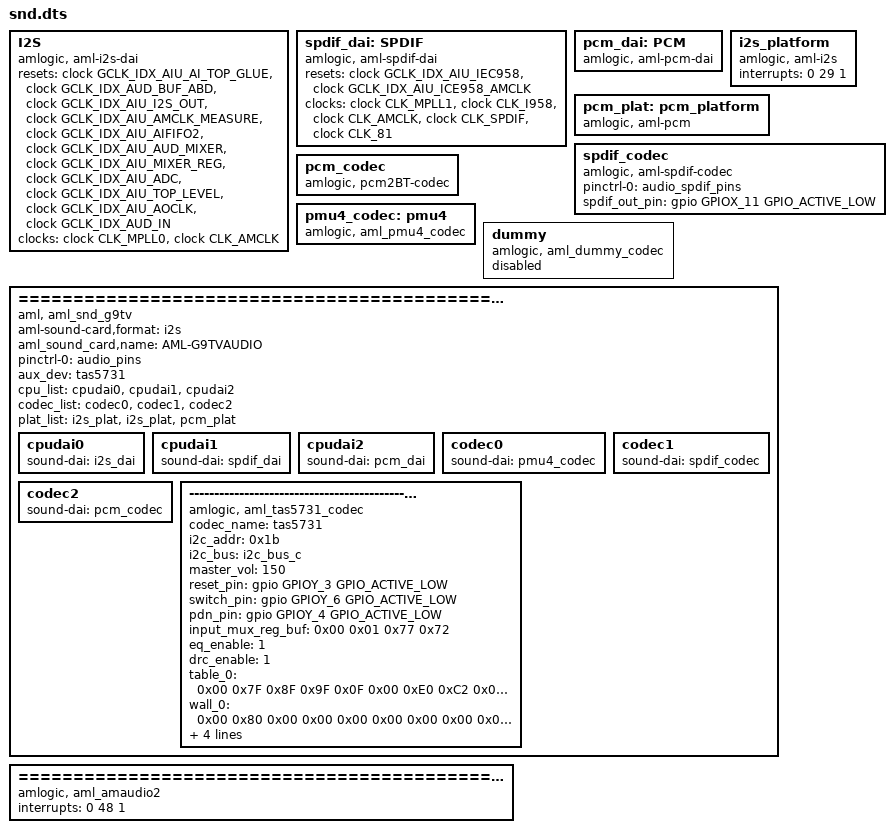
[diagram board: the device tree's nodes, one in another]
	/* AUDIO MESON8 DEVICES */
================================================================================================
	i2s_dai: I2S {
		#sound-dai-cells = <0>;
		resets = <
			&clock GCLK_IDX_AIU_AI_TOP_GLUE
			&clock GCLK_IDX_AUD_BUF_ABD
			&clock GCLK_IDX_AIU_I2S_OUT
			&clock GCLK_IDX_AIU_AMCLK_MEASURE
			&clock GCLK_IDX_AIU_AIFIFO2
			&clock GCLK_IDX_AIU_AUD_MIXER
			&clock GCLK_IDX_AIU_MIXER_REG
			&clock GCLK_IDX_AIU_ADC
			&clock GCLK_IDX_AIU_TOP_LEVEL
			&clock GCLK_IDX_AIU_AOCLK
			&clock GCLK_IDX_AUD_IN
		>;
		reset-names =
			"top_glue",
			"aud_buf",
			"i2s_out",
			"amclk_measure",
			"aififo2",
			"aud_mixer",
			"mixer_reg",
			"adc",
			"top_level",
			"aoclk",
			"aud_in";
		clocks = <&clock CLK_MPLL0>,
			<&clock CLK_AMCLK>;
		clock-names = "mpll0", "mclk";
		compatible = "amlogic, aml-i2s-dai";
	};
	spdif_dai: SPDIF {
		#sound-dai-cells = <0>;
		compatible = "amlogic, aml-spdif-dai";
		resets = <
			&clock GCLK_IDX_AIU_IEC958
			&clock GCLK_IDX_AIU_ICE958_AMCLK
		>;
		reset-names =
			"iec958",
			"iec958_amclk";
		clocks = <&clock CLK_MPLL1>,
			<&clock CLK_I958>,
			<&clock CLK_AMCLK>,
			<&clock CLK_SPDIF>,
			<&clock CLK_81>;
		clock-names = "mpll1", "i958", "mclk", "spdif", "clk_81";
	};
	pcm_dai: PCM {
		#sound-dai-cells = <0>;
		compatible = "amlogic, aml-pcm-dai";
	};
================================================================================================
	i2s_plat: i2s_platform {
		compatible = "amlogic, aml-i2s";
		interrupts = <0 29 1>;
	};
	pcm_plat: pcm_platform {
		compatible = "amlogic, aml-pcm";
	};
================================================================================================
	spdif_codec: spdif_codec{
		#sound-dai-cells = <0>;
		compatible = "amlogic, aml-spdif-codec";
		pinctrl-names = "aml_audio_spdif";
		pinctrl-0 = <&audio_spdif_pins>;
		spdif_out_pin = <&gpio GPIOX_11 GPIO_ACTIVE_LOW>;
	};
	pcm_codec: pcm_codec{
		#sound-dai-cells = <0>;
		compatible = "amlogic, pcm2BT-codec";
	};
	pmu4_codec:pmu4{
		#sound-dai-cells = <0>;
		compatible = "amlogic, aml_pmu4_codec";
		status = "okay";
	};
================================================================================================
	/* endof AUDIO MESON8 DEVICES */

	/* AUDIO board specific */
	dummy_codec:dummy{
		#sound-dai-cells = <0>;
		compatible = "amlogic, aml_dummy_codec";
		status = "disable";
	};

================================================================================================
	aml_g9tv_snd {
		compatible = "aml, aml_snd_g9tv";
		status = "okay";
		aml-sound-card,format = "i2s";
		aml_sound_card,name = "AML-G9TVAUDIO";
		pinctrl-names = "aml_snd_g9tv";
		pinctrl-0 = <&audio_pins>;
	-------------------------------------------------------
		aux_dev = "tas5731";
	-------------------------------------------------------
		cpu_list = <&cpudai0 &cpudai1 &cpudai2>;
	-------------------------------------------------------
		codec_list = <&codec0 &codec1 &codec2>;
	-------------------------------------------------------
		plat_list = <&i2s_plat &i2s_plat &pcm_plat>;
	-------------------------------------------------------
		cpudai0: cpudai0 {
			sound-dai = <&i2s_dai>;
		};
		cpudai1: cpudai1 {
			sound-dai = <&spdif_dai>;
		};
		cpudai2: cpudai2 {
			sound-dai = <&pcm_dai>;
		};
	-------------------------------------------------------
		codec0: codec0 {
			sound-dai = <&pmu4_codec>;
			//sound-dai = <&dummy_codec>;
		};
		codec1: codec1 {
			sound-dai = <&spdif_codec>;
		};
		codec2: codec2 {
			sound-dai = <&pcm_codec>;
		};
	-------------------------------------------------------
		tas5731 {
			compatible = "amlogic, aml_tas5731_codec";
			codec_name = "tas5731";
			status = "okay";
			i2c_addr = <0x1b>;
			i2c_bus = "i2c_bus_c";
			master_vol = <150>;
			reset_pin = <&gpio GPIOY_3 GPIO_ACTIVE_LOW>; // RESET_GATE:G5
			switch_pin = <&gpio GPIOY_6 GPIO_ACTIVE_LOW>;
			pdn_pin=<&gpio GPIOY_4 GPIO_ACTIVE_LOW>;
			input_mux_reg_buf = /bits/ 8 <0x00 0x01 0x77 0x72>;/*AD mode*/
			eq_enable = <1>;
			drc_enable = <1>;
			table_0 = /bits/ 8 <
                0x00 0x7F 0x8F 0x9F 0x0F 0x00 0xE0 0xC2 0x00 0x7F 0x8F 0x9F 0x00 0xFF 0x1E 0x65 0x0F 0x80 0xDF 0xE9 /* 0X29---ch1 */
			>;
			wall_0 = /bits/ 8 <
				0x00 0x80 0x00 0x00 0x00 0x00 0x00 0x00 0x00 0x00 0x00 0x00 0x00 0x00 0x00 0x00 0x00 0x00 0x00 0x00
			>;
			drc1_table_0 = /bits/ 8 <
				0x00 0x00 0x44 0x32 0x00 0x7F 0xBB 0xCD /* 0X3A---drc1 */
				0x00 0x0C 0xA9 0x92 0x00 0x73 0x56 0x6D /* 0X3B---drc1 */
				0x00 0x00 0x01 0x5D 0x00 0x7F 0xFE 0xA2 /* 0X3C---drc1 */
			>;
			drc2_table_0 = /bits/ 8 <
				0x00 0x00 0x44 0x32 0x00 0x7F 0xBB 0xCD /* 0X3D---drc2 */
				0x00 0x0C 0xA9 0x91 0x00 0x73 0x56 0x6C /* 0X3E---drc2 */
				0x00 0x00 0x01 0x5D 0x00 0x7F 0xFE 0xA1 /* 0X3F---drc2 */
			>;
		};
 	};
================================================================================================
	amaudio2 {
		compatible = "amlogic, aml_amaudio2";
		status = "okay";
		interrupts = <0 48 1>;
 	};
